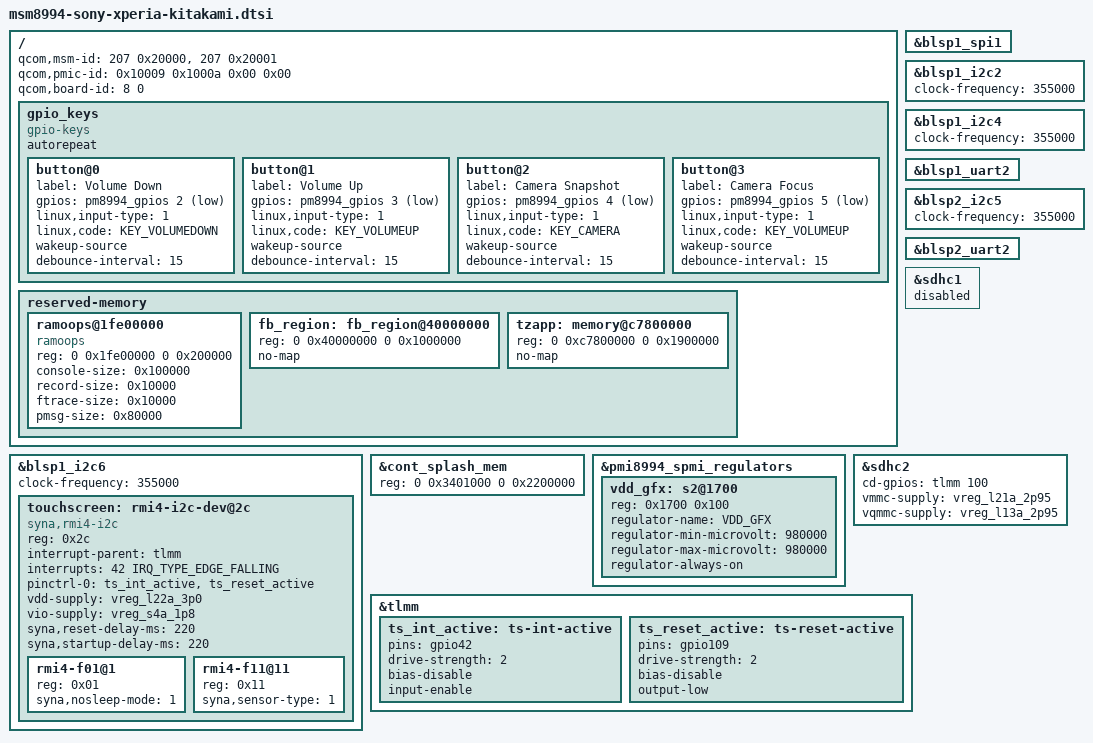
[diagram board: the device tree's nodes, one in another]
// SPDX-License-Identifier: BSD-3-Clause
/*
 * Copyright (c) 2020, Konrad Dybcio <konrad.dybcio@somainline.org>
 */

#include "msm8994.dtsi"
#include "pm8994.dtsi"
#include "pmi8994.dtsi"
#include "msm8994-rpm.dtsi"
#include <dt-bindings/gpio/gpio.h>
#include <dt-bindings/input/gpio-keys.h>

/ {
	/* required for bootloader to select correct board */

	/*
	 * We support MSM8994 v2 (0x20000) and v2.1 (0x20001).
	 * The V1 chip (0x0 and 0x10000) is significantly different
	 * and requires driver-side changes (including CPR, be warned!!).
	 * Besides that, it's very rare.
	 */
	qcom,msm-id = <207 0x20000>, <207 0x20001>;
	/* We only use pm8994+pmi8994. */
	qcom,pmic-id = <0x10009 0x1000a 0x00 0x00>;
	/* This property is shared across all kitakami devices. */
	qcom,board-id = <8 0>;

	/* Kitakami firmware doesn't support PSCI */
	/delete-node/ psci;

	gpio_keys {
		compatible = "gpio-keys";
		#address-cells = <1>;
		#size-cells = <0>;
		autorepeat;

		button@0 {
			label = "Volume Down";
			gpios = <&pm8994_gpios 2 GPIO_ACTIVE_LOW>;
			linux,input-type = <1>;
			linux,code = <KEY_VOLUMEDOWN>;
			wakeup-source;
			debounce-interval = <15>;
		};

		button@1 {
			label = "Volume Up";
			gpios = <&pm8994_gpios 3 GPIO_ACTIVE_LOW>;
			linux,input-type = <1>;
			linux,code = <KEY_VOLUMEUP>;
			wakeup-source;
			debounce-interval = <15>;
		};

		button@2 {
			label = "Camera Snapshot";
			gpios = <&pm8994_gpios 4 GPIO_ACTIVE_LOW>;
			linux,input-type = <1>;
			linux,code = <KEY_CAMERA>;
			wakeup-source;
			debounce-interval = <15>;
		};

		button@3 {
			label = "Camera Focus";
			gpios = <&pm8994_gpios 5 GPIO_ACTIVE_LOW>;
			linux,input-type = <1>;
			linux,code = <KEY_VOLUMEUP>;
			wakeup-source;
			debounce-interval = <15>;
		};
	};

	reserved-memory {
		/* This is for getting crash logs using Android downstream kernels */
		ramoops@1fe00000 {
			compatible = "ramoops";
			reg = <0 0x1fe00000 0 0x200000>;
			console-size = <0x100000>;
			record-size = <0x10000>;
			ftrace-size = <0x10000>;
			pmsg-size = <0x80000>;
		};

		fb_region: fb_region@40000000 {
			reg = <0 0x40000000 0 0x1000000>;
			no-map;
		};

		tzapp: memory@c7800000 {
			reg = <0 0xc7800000 0 0x1900000>;
			no-map;
		};
	};
};

&blsp1_spi1 {
	status = "okay";

	/* FPC fingerprint reader */
};

/* I2C1 is disabled on this board */

&blsp1_i2c2 {
	status = "okay";
	clock-frequency = <355000>;

	/* NXP PN547 NFC */
};

&blsp1_i2c4 {
	status = "okay";
	clock-frequency = <355000>;

	/* Empty but active */
};

&blsp1_i2c6 {
	status = "okay";
	clock-frequency = <355000>;

	touchscreen: rmi4-i2c-dev@2c {
		compatible = "syna,rmi4-i2c";
		reg = <0x2c>;
		#address-cells = <1>;
		#size-cells = <0>;

		interrupt-parent = <&tlmm>;
		interrupts = <42 IRQ_TYPE_EDGE_FALLING>;

		pinctrl-names = "default";
		pinctrl-0 = <&ts_int_active &ts_reset_active>;

		vdd-supply = <&vreg_l22a_3p0>;
		vio-supply = <&vreg_s4a_1p8>;

		syna,reset-delay-ms = <220>;
		syna,startup-delay-ms = <220>;

		rmi4-f01@1 {
			reg = <0x01>;
			syna,nosleep-mode = <1>;
		};

		rmi4-f11@11 {
			reg = <0x11>;
			syna,sensor-type = <1>;
		};
	};
};

&blsp1_uart2 {
	status = "okay";
};

&blsp2_i2c5 {
	status = "okay";
	clock-frequency = <355000>;

	/* sii8620 HDMI/MHL bridge */
};

&blsp2_uart2 {
	status = "okay";
};

/*
 * Kitakami bootloader only turns cont_splash on when it detects
 * specific downstream MDSS/backlight nodes in the active DTB.
 * One way to use that framebuffer is to load a secondary instance of
 * LK with the downstream DTB appended and then, only from there, load
 * mainline Linux.
 */
&cont_splash_mem {
	reg = <0 0x3401000 0 0x2200000>;
};

&pmi8994_spmi_regulators {
	/*
	 * Yeah, this one *is* managed by RPMPD, but also needs
	 * to be hacked up as a-o due to the GPU device only accepting a single
	 * power domain.. which still isn't enough and forces us to bind
	 * OXILI_CX and OXILI_GX together!
	 */
	vdd_gfx: s2@1700 {
		reg = <0x1700 0x100>;
		regulator-name = "VDD_GFX";
		regulator-min-microvolt = <980000>;
		regulator-max-microvolt = <980000>;

		/* hack until we rig up the gpu consumer */
		regulator-always-on;
	};
};

&sdhc1 {
	/*
	 * There is an issue with the eMMC causing permanent
	 * damage to the card if a quirk isn't addressed.
	 * Until it's fixed, disable the MMC so as not to brick
	 * devices.
	 */
	status = "disabled";

	/*
	 * Downstream pushes 2.95V to the sdhci device,
	 * but upstream driver REALLY wants to make vmmc 1.8v
	 * cause of the hs400-1_8v mode. MMC works fine without
	 * that regulator, so let's not use it for now.
	 * vqmmc is also disabled cause driver stll complains.
	 *
	 * vmmc-supply = <&vreg_l20a_2p95>;
	 * vqmmc-supply = <&vreg_s4a_1p8>;
	 */
};

&sdhc2 {
	status = "okay";

	cd-gpios = <&tlmm 100 0>;
	vmmc-supply = <&vreg_l21a_2p95>;
	vqmmc-supply = <&vreg_l13a_2p95>;
};

&tlmm {
	ts_int_active: ts-int-active {
		pins = "gpio42";
		drive-strength = <2>;
		bias-disable;
		input-enable;
	};

	ts_reset_active: ts-reset-active {
		pins = "gpio109";
		drive-strength = <2>;
		bias-disable;
		output-low;
	};
};
